# SAM9X75D5M register map
Vendor: Microchip Technology; Series: SAM9X7; File version: 0
Registers are 32-bit, read-write, reset 0x0 unless marked. A register's access mark holds for its fields unless they carry their own. Offsets are from the block's base; [hi:lo] are bit positions; {n}, {i} and the like mark numbered series; 'fields as' and 'values as' point back to an identical list.

## FLEXCOM0 (part 2 of 2) — Flexible Serial Communication
Base 0xF801C000; register names take the prefix FLEXCOM_
Same registers: FLEXCOM4 0xF0000000, FLEXCOM5 0xF0004000, FLEXCOM11 0xF0020000, FLEXCOM12 0xF0024000, FLEXCOM6 0xF8010000, FLEXCOM7 0xF8014000, FLEXCOM8 0xF8018000, FLEXCOM1 0xF8020000, FLEXCOM2 0xF8024000, FLEXCOM3 0xF8028000, FLEXCOM9 0xF8040000, FLEXCOM10 0xF8044000
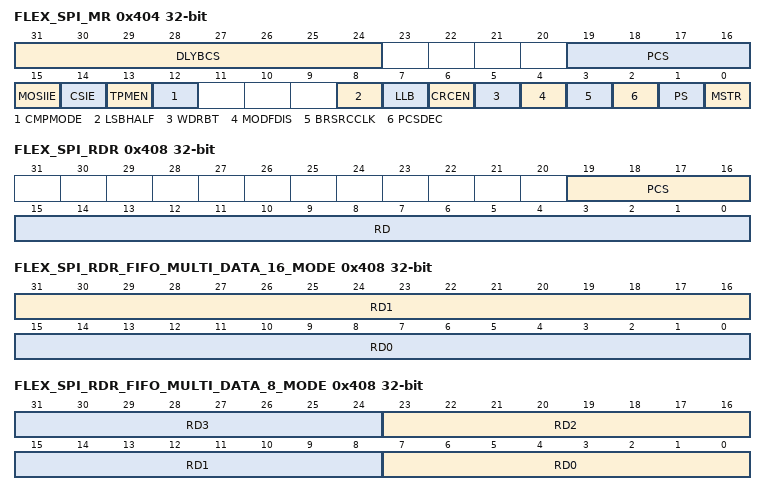
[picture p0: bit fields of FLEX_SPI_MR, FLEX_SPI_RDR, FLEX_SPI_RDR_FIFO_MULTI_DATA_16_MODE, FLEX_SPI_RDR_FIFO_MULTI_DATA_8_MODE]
0x404 FLEX_SPI_MR — SPI Mode Register
  [31:24] DLYBCS — Delay Between Chip Selects
  [19:16] PCS — Peripheral Chip Select
  [15] MOSIIE — MOSI Inversion Enable
    0=MOSI input is not inverted; 1=MOSI input is internally inverted before being processed by the SPI
  [14] CSIE — Chip Select Inversion Enable
    0=Chip select NPCS active polarity is low; 1=Chip select NPCS active polarity is high
  [13] TPMEN — Two-Pin Mode Enable
    0=Two-Pin mode is disabled; 1=Two-Pin mode is enabled
  [12] CMPMODE — Comparison Mode
    0=FLAG_ONLY (Any character is received and comparison function drives CMP flag.); 1=START_CONDITION (Comparison condition must be met to start reception of all incoming characters until REQCLR is set.)
  [8] LSBHALF — Last Bit Half Period Compatibility
    0=Normal SPI mode of operation: all bits have a 1-bit time duration (standard SPI mode); 1=Compatibility mode when connected to an SPI client having only a half bit period duration time for the last bit of the frame (non-standard SPI mode)
  [7] LLB — Local Loopback Enable
    0=Local loopback path disabled; 1=Local loopback path enabled
  [6] CRCEN — CRC Enable
    0=CRC calculation is disabled; 1=CRC calculation is enabled. BITS in FLEX_SPI_CSRx registers must be at value '0'.
  [5] WDRBT — Wait Data Read Before Transfer
    0=No Effect. In Host mode, a transfer can be initiated regardless of the FLEX_SPI_RDR state.; 1=In Host mode, a transfer can start only if FLEX_SPI_RDR is empty, i.e., does not contain any unread data. This mode prevents overrun error in reception.
  [4] MODFDIS — Mode Fault Detection
    0=Mode fault detection is enabled; 1=Mode fault detection is disabled
  [3] BRSRCCLK — Bit Rate Source Clock
    0=PERIPH_CLK (The peripheral clock is the source clock for the bit rate generation.); 1=GCLK (GCLK is the source clock for the bit rate generation, thus the bit rate can be independent of the core/peripheral clock.)
  [2] PCSDEC — Chip Select Decode
    0=The chip selects are directly connected to a peripheral device; 1=The four NPCS chip select lines are connected to a 4- to 16-bit decoder
  [1] PS — Peripheral Select
    0=Fixed Peripheral Select; 1=Variable Peripheral Select
  [0] MSTR — Host/Client Mode
    0=SPI is in Client mode; 1=SPI is in Host mode
0x408 FLEX_SPI_RDR ro — SPI Receive Data Register
  [19:16] PCS — Peripheral Chip Select
  [15:0] RD — Receive Data
0x408 FLEX_SPI_RDR_FIFO_MULTI_DATA_16_MODE ro (alternate view of FLEX_SPI_RDR) — SPI Receive Data Register
  [31:16] RD1 — Receive Data
  [15:0] RD0 — Receive Data
0x408 FLEX_SPI_RDR_FIFO_MULTI_DATA_8_MODE ro (alternate view of FLEX_SPI_RDR) — SPI Receive Data Register
  [8n+7:8n] RD{n} (n=0..3) — Receive Data
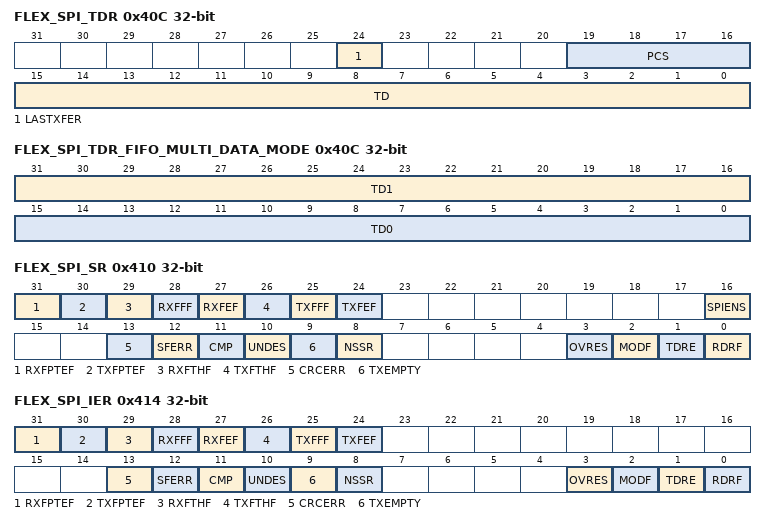
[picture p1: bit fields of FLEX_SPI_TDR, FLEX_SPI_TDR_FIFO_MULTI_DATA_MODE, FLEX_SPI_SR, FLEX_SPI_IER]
0x40C FLEX_SPI_TDR wo — SPI Transmit Data Register
  [24] LASTXFER — Last Transfer
    0=No effect; 1=The current NPCS is de-asserted after the transfer of the character written in TD. When FLEX_SPI_CSRx.CSAAT is set, the communication with the current serial peripheral can be closed by raising the corresponding NPCS line as soon as TD transfer is completed.
  [19:16] PCS — Peripheral Chip Select
  [15:0] TD — Transmit Data
0x40C FLEX_SPI_TDR_FIFO_MULTI_DATA_MODE wo (alternate view of FLEX_SPI_TDR) — SPI Transmit Data Register
  [31:16] TD1 — Transmit Data
  [15:0] TD0 — Transmit Data
0x410 FLEX_SPI_SR ro — SPI Status Register
  [31] RXFPTEF — Receive FIFO Pointer Error Flag
    0=No Receive FIFO pointer occurred; 1=Receive FIFO pointer error occurred. Receiver must be reset
  [30] TXFPTEF — Transmit FIFO Pointer Error Flag
    0=No Transmit FIFO pointer occurred; 1=Transmit FIFO pointer error occurred. Transceiver must be reset
  [29] RXFTHF — Receive FIFO Threshold Flag
    0=Number of unread data in Receive FIFO is below RXFTHRES threshold or RXFTH flag has been cleared; 1=Number of unread data in Receive FIFO has reached RXFTHRES threshold (changing states from 'below threshold' to 'equal to or above threshold')
  [28] RXFFF — Receive FIFO Full Flag
    0=Receive FIFO is not empty or RXFE flag has been cleared; 1=Receive FIFO has been filled (changing states from 'not full' to 'full')
  [27] RXFEF — Receive FIFO Empty Flag
    0=Receive FIFO is not empty or RXFE flag has been cleared; 1=Receive FIFO has been emptied (changing states from 'not empty' to 'empty')
  [26] TXFTHF — Transmit FIFO Threshold Flag (cleared on read)
    0=Number of data in Transmit FIFO is above TXFTHRES threshold; 1=Number of data in Transmit FIFO has reached TXFTHRES threshold since the last read of FLEX_SPI_SR
  [25] TXFFF — Transmit FIFO Full Flag (cleared on read)
    0=Transmit FIFO is not full or TXFF flag has been cleared; 1=Transmit FIFO has been filled since the last read of FLEX_SPI_SR
  [24] TXFEF — Transmit FIFO Empty Flag (cleared on read)
    0=Transmit FIFO is not empty; 1=Transmit FIFO has been emptied since the last read of FLEX_SPI_SR
  [16] SPIENS — SPI Enable Status
    0=SPI is disabled; 1=SPI is enabled
  [13] CRCERR — CRC Error (cleared on read)
    0=CRC calculation is disabled or no received frame contains a CRC error since the last read of FLEX_SPI_SR; 1=Since the last read of FLEX_SPI_SR, a received frame contains a CRC error
  [12] SFERR — Client Mode Frame Error (cleared on read)
    0=No frame error has been detected for a client access since the last read of FLEX_SPI_SR; 1=In Client mode, the chip select raised while the character defined in FLEX_SPI_CSR0.BITS was not complete
  [11] CMP — Comparison Status (cleared on read)
    0=No received character matched the comparison criteria programmed in VAL1 and VAL2 fields in FLEX_SPI_CMPR since the last read of FLEX_SPI_SR; 1=A received character matched the comparison criteria since the last read of FLEX_SPI_SR
  [10] UNDES — Underrun Error Status (Client mode only) (cleared on read)
    0=No underrun has been detected since the last read of FLEX_SPI_SR; 1=A transfer starts whereas no data has been loaded in FLEX_SPI_TDR, cleared when FLEX_SPI_SR is read
  [9] TXEMPTY — Transmission Registers Empty (cleared by writing FLEX_SPI_TDR)
    0=As soon as data is written in FLEX_SPI_TDR; 1=FLEX_SPI_TDR and internal shift register are empty. If a transfer delay has been defined, TXEMPTY is set after the end of this delay.
  [8] NSSR — NSS Rising (cleared on read)
    0=No rising edge detected on NSS pin since the last read of FLEX_SPI_SR; 1=A rising edge occurred on NSS pin since the last read of FLEX_SPI_SR
  [3] OVRES — Overrun Error Status (cleared on read)
    0=No overrun has been detected since the last read of FLEX_SPI_SR; 1=An overrun has occurred since the last read of FLEX_SPI_SR
  [2] MODF — Mode Fault Error (cleared on read)
    0=No mode fault has been detected since the last read of FLEX_SPI_SR; 1=A mode fault occurred since the last read of FLEX_SPI_SR
  [1] TDRE — Transmit Data Register Empty (cleared by writing FLEX_SPI_TDR)
    0=Data has been written to FLEX_SPI_TDR and not yet transferred to the internal shift register; 1=The last data written to FLEX_SPI_TDR has been transferred to the internal shift register
  [0] RDRF — Receive Data Register Full (cleared by reading FLEX_SPI_RDR)
    0=No data has been received since the last read of FLEX_SPI_RDR; 1=Data has been received and the received data has been transferred from the internal shift register to FLEX_SPI_RDR since the last read of FLEX_SPI_RDR
0x414 FLEX_SPI_IER wo — SPI Interrupt Enable Register
  [31] RXFPTEF — RXFPTEF Interrupt Enable
  [30] TXFPTEF — TXFPTEF Interrupt Enable
  [29] RXFTHF — RXFTHF Interrupt Enable
  [28] RXFFF — RXFFF Interrupt Enable
  [27] RXFEF — RXFEF Interrupt Enable
  [26] TXFTHF — TXFTHF Interrupt Enable
  [25] TXFFF — TXFFF Interrupt Enable
  [24] TXFEF — TXFEF Interrupt Enable
  [13] CRCERR — CRC Error Interrupt Enable
  [12] SFERR — Client Mode Frame Error Interrupt Enable
  [11] CMP — Comparison Interrupt Enable
  [10] UNDES — Underrun Error Interrupt Enable
  [9] TXEMPTY — Transmission Registers Empty Enable
  [8] NSSR — NSS Rising Interrupt Enable
  [3] OVRES — Overrun Error Interrupt Enable
  [2] MODF — Mode Fault Error Interrupt Enable
  [1] TDRE — SPI Transmit Data Register Empty Interrupt Enable
  [0] RDRF — Receive Data Register Full Interrupt Enable
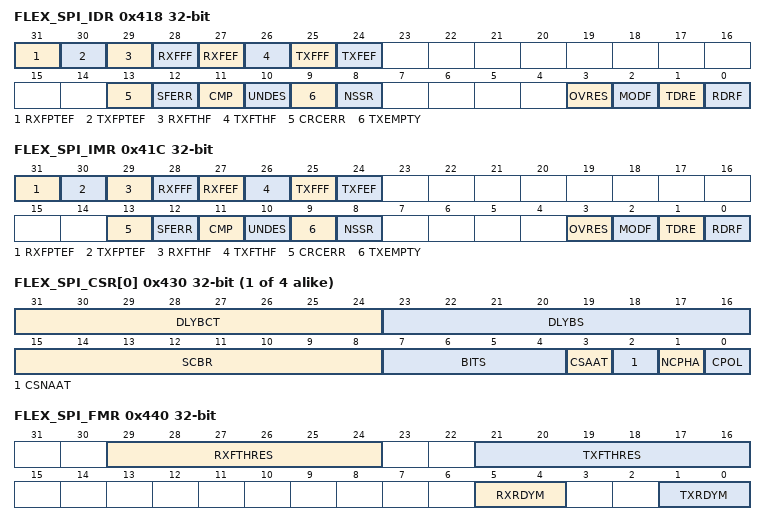
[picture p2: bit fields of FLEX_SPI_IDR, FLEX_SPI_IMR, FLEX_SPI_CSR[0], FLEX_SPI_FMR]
0x418 FLEX_SPI_IDR wo — SPI Interrupt Disable Register
  [31] RXFPTEF — RXFPTEF Interrupt Disable
  [30] TXFPTEF — TXFPTEF Interrupt Disable
  [29] RXFTHF — RXFTHF Interrupt Disable
  [28] RXFFF — RXFFF Interrupt Disable
  [27] RXFEF — RXFEF Interrupt Disable
  [26] TXFTHF — TXFTHF Interrupt Disable
  [25] TXFFF — TXFFF Interrupt Disable
  [24] TXFEF — TXFEF Interrupt Disable
  [13] CRCERR — CRC Error Interrupt Disable
  [12] SFERR — Client Mode Frame Error Interrupt Disable
  [11] CMP — Comparison Interrupt Disable
  [10] UNDES — Underrun Error Interrupt Disable
  [9] TXEMPTY — Transmission Registers Empty Disable
  [8] NSSR — NSS Rising Interrupt Disable
  [3] OVRES — Overrun Error Interrupt Disable
  [2] MODF — Mode Fault Error Interrupt Disable
  [1] TDRE — SPI Transmit Data Register Empty Interrupt Disable
  [0] RDRF — Receive Data Register Full Interrupt Disable
0x41C FLEX_SPI_IMR ro — SPI Interrupt Mask Register
  [31] RXFPTEF — RXFPTEF Interrupt Mask
  [30] TXFPTEF — TXFPTEF Interrupt Mask
  [29] RXFTHF — RXFTHF Interrupt Mask
  [28] RXFFF — RXFFF Interrupt Mask
  [27] RXFEF — RXFEF Interrupt Mask
  [26] TXFTHF — TXFTHF Interrupt Mask
  [25] TXFFF — TXFFF Interrupt Mask
  [24] TXFEF — TXFEF Interrupt Mask
  [13] CRCERR — CRC Error Interrupt Mask
  [12] SFERR — Client Mode Frame Error Interrupt Mask
  [11] CMP — Comparison Interrupt Mask
  [10] UNDES — Underrun Error Interrupt Mask
  [9] TXEMPTY — Transmission Registers Empty Mask
  [8] NSSR — NSS Rising Interrupt Mask
  [3] OVRES — Overrun Error Interrupt Mask
  [2] MODF — Mode Fault Error Interrupt Mask
  [1] TDRE — SPI Transmit Data Register Empty Interrupt Mask
  [0] RDRF — Receive Data Register Full Interrupt Mask
{0x430+4i} FLEX_SPI_CSR[{i}] (i=0..3) — SPI Chip Select Register x
  [31:24] DLYBCT — Delay Between Consecutive Transfers
  [23:16] DLYBS — Delay Before SPCK
  [15:8] SCBR — Serial Clock Bit Rate
  [7:4] BITS — Bits Per Transfer
    {v}={v+8}_BIT ({v+8} bits for transfer) (v=0..8)
  [3] CSAAT — Chip Select Active After Transfer
    0=The Peripheral Chip Select Line rises as soon as the last transfer is achieved; 1=The Peripheral Chip Select does not rise after the last transfer is achieved. It remains active until a new transfer is requested on a different chip select.
  [2] CSNAAT — Chip Select Not Active After Transfer (Ignored if CSAAT = 1)
    0=The Peripheral Chip Select does not rise between two transfers if the FLEX_SPI_TDR is reloaded before the end of the first transfer and if the two transfers occur on the same Chip Select; 1=The Peripheral Chip Select rises systematically after each transfer performed on the same client. It remains inactive after the end of transfer for a minimal duration of:
  [1] NCPHA — Clock Phase
    0=Data are changed on the leading edge of SPCK and captured on the following edge of SPCK; 1=Data are captured on the leading edge of SPCK and changed on the following edge of SPCK
  [0] CPOL — Clock Polarity
    0=The inactive state value of SPCK is logic level zero; 1=The inactive state value of SPCK is logic level one
0x440 FLEX_SPI_FMR — SPI FIFO Mode Register
  [29:24] RXFTHRES — Receive FIFO Threshold
  [21:16] TXFTHRES — Transmit FIFO Threshold
  [5:4] RXRDYM — Receive Data Register Full Mode
    0=ONE_DATA (RDRF will be at level '1' when at least one unread data is in the receive FIFO. When DMA is enabled to transfer data and FLEX_SPI_CSR0.BITS=0 (8 bits transfered on SPI line), the chunk of 1 byte must be configured in the DMA. When FLEX_SPI_CSR0.BITS>0 (9 to 16 bits transfered on SPI line), the chunk of 1 halfword must be configured in the DMA. If the transfer is performed by software, the access type can be defined as byte or halfword depending on FLEX_SPI_CSR0.BITS.); 1=TWO_DATA (RDRF will be at level '1' when at least two unread data are in the receive FIFO. To minimize system bus load, when DMA is enabled to transfer data and FLEX_SPI_CSR0.BITS=0 (8 bits transfered on SPI line), the chunk of 1 halfword (1 halfword carries 2 bytes) must be configured in the DMA. When FLEX_SPI_CSR0.BITS>0 (9 to 16 bits transfered on SPI line), the chunk of 1 word (1 word carries 2 halfwords) must be configured in the DMA. If the transfer is performed by software, the access type can be defined as halfword (2 bytes per access, 1 access when FLEX_SPI_CSR0.BITS=0), or word (2 halfwords per access, 2 accesses when FLEX_SPI_CSR0.BITS>0).); 2=FOUR_DATA (RDRF will be at level '1' when at least four unread data are in the receive FIFO. To minimize system bus load, when DMA is enabled to transfer data and FLEX_SPI_CSR0.BITS=0 (8 bits transfered on SPI line), the chunk of 1 word (1 halfword carries 4 bytes) must be configured in the DMA. When FLEX_SPI_CSR0.BITS>0 (9 to 16 bits transfered on SPI line), the chunk of 2 words (1 word carries 4 bytes) must be configured in the DMA. If the transfer is performed by software, the access type can be defined as word (4 bytes per access, 1 access when FLEX_SPI_CSR0.BITS=0 or 2 halfwords per access, 2 accesses when FLEX_SPI_CSR0.BITS>0).)
  [1:0] TXRDYM — Transmit Data Register Empty Mode
    0=ONE_DATA (TDRE will be at level '1' when at least one data can be written in the transmit FIFO. When DMA is enabled to transfer data, the chunk of 1 data (byte or halfword) must be configured in the DMA depending on FLEX_SPI_CSR0.BITS. If the transfer is performed by software, the access type (byte, halfword) must be defined depending on FLEX_SPI_CSR0.BITS.); 1=TWO_DATA (TDRE will be at level '1' when at least two data can be written in the transmit FIFO. FIFO. To minimize system bus load, when DMA is enabled to transfer data, the chunk of 1 word (1 word carries 2 data) must be configured in the DMA. If the transfer is performed by software, the access type must be defined as word (2 data per access, 1 access).)
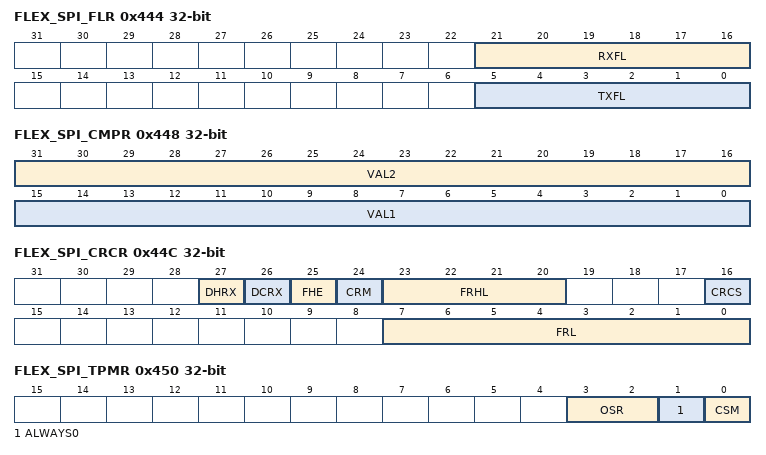
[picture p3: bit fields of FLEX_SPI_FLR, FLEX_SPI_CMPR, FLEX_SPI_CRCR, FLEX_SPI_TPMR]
0x444 FLEX_SPI_FLR ro — SPI FIFO Level Register
  [21:16] RXFL — Receive FIFO Level
    0=There is no unread data in the Receive FIFO
  [5:0] TXFL — Transmit FIFO Level
    0=There is no data in the Transmit FIFO
0x448 FLEX_SPI_CMPR — SPI Comparison Register
  [31:16] VAL2 — Second Comparison Value for Received Character
  [15:0] VAL1 — First Comparison Value for Received Character
0x44C FLEX_SPI_CRCR — SPI CRC Register
  [27] DHRX — Disable Header Receiving
    0=Header is received and supplied to FLEX_SPI_RDR as a classic data; 1=Header is received and checked but not supplied to FLEX_SPI_RDR (RDRF will not rise upon Header receiving)
  [26] DCRX — Disable CRC Receiving
    0=CRC is received and supplied to FLEX_SPI_RDR as a classic data; 1=CRC is received and checked but not supplied to FLEX_SPI_RDR (RDRF will not rise upon CRC receiving)
  [25] FHE — Frame Header Excluded
    0=The frame header is included in the CRC calculation; 1=The frame header is excluded from the CRC calculation
  [24] CRM — Continuous Read Mode
    0=A header is sent every frame in case of contiguous frames (without de-asserting the corresponding NPCS); 1=A header is sent only on the first frame in case of contiguous frames (without de-asserting the corresponding NPCS)
  [23:20] FRHL — Frame Header Length
  [16] CRCS — CRC Size
    0=16B_CRC (CRC size is 16 bits.); 1=32B_CRC (CRC size is 32 bits.)
  [7:0] FRL — Frame Length
0x450 FLEX_SPI_TPMR — SPI Two-Pin Mode Register
  [3:2] OSR — OverSampling Rate
  [1] ALWAYS0 — Always Written to 0
  [0] CSM — Chip Select Mode
    0=Chip select is not driven; 1=Chip select is driven and can be used to control enable pin of external device. Depending on FLEX_SPI_MR.PCSDEC, an external decoder can be used to minimize the number of IOs used.
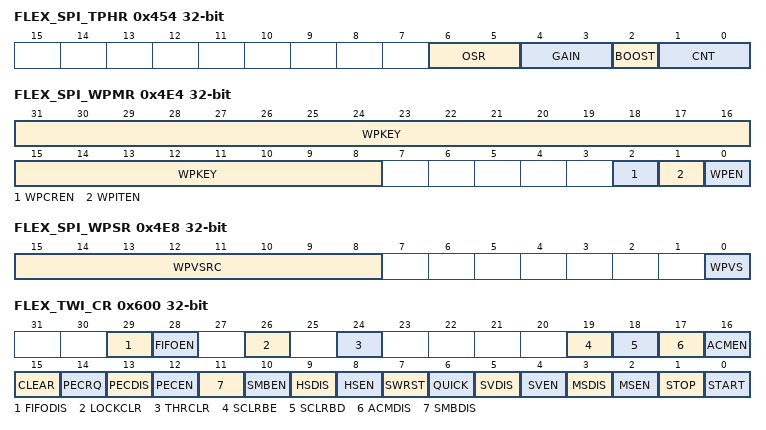
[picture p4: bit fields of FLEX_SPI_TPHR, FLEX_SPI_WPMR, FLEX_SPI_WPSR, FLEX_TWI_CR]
0x454 FLEX_SPI_TPHR ro — SPI Two-Pin Header Register
  [6:5] OSR — OverSampling Rate
  [4:3] GAIN
  [2] BOOST — Current Boost
  [1:0] CNT — Frame Counter
0x4E4 FLEX_SPI_WPMR — SPI Write Protection Mode Register
  [31:8] WPKEY — Write Protection Key
    0x535049=PASSWD (Writing any other value in this field aborts the write operation of bits WPEN, WPITEN and WPCREN. Always reads as 0)
  [2] WPCREN — Write Protection Control Enable
    0=Disables the write protection on control register if WPKEY corresponds to 0x535049 ('SPI' in ASCII); 1=Enables the write protection on control register if WPKEY corresponds to 0x535049 ('SPI' in ASCII)
  [1] WPITEN — Write Protection Interrupt Enable
    0=Disables the write protection on interrupt registers if WPKEY corresponds to 0x535049 ('SPI' in ASCII); 1=Enables the write protection on interrupt registers if WPKEY corresponds to 0x535049 ('SPI' in ASCII)
  [0] WPEN — Write Protection Enable
    0=Disables the write protection if WPKEY corresponds to 0x535049 ('SPI' in ASCII); 1=Enables the write protection if WPKEY corresponds to 0x535049 ('SPI' in ASCII)
0x4E8 FLEX_SPI_WPSR ro — SPI Write Protection Status Register
  [15:8] WPVSRC — Write Protection Violation Source
  [0] WPVS — Write Protection Violation Status
    0=No write protect violation has occurred since the last read of FLEX_SPI_WPSR; 1=A write protect violation has occurred since the last read of FLEX_SPI_WPSR. If this violation is an unauthorized
0x600 FLEX_TWI_CR wo — TWI Control Register
  [29] FIFODIS — FIFO Disable
    0=No effect; 1=Disable the Transmit and Receive FIFOs
  [28] FIFOEN — FIFO Enable
    0=No effect; 1=Enable the Transmit and Receive FIFOs
  [26] LOCKCLR — Lock Clear
    0=No effect; 1=Clear the TWI FSM lock
  [24] THRCLR — Transmit Holding Register Clear
    0=No effect; 1=Clear the Transmit Holding Register and set TXRDY, TXCOMP flags
  [19] SCLRBE — SCL Rise Boost Enable
    0=No effect; 1=SCL rise time is boosted in High-Speed mode. Duration of the boost is configured with FLEX_TWI_MMR.SCLRBL. See Section 10.3.12.2 'SCL Rising Time Control' for details.
  [18] SCLRBD — SCL Rise Boost Disable
    0=No effect; 1=SCL rise time boost is disabled. See Section 10.3.12.2 'SCL Rising Time Control' for details.
  [17] ACMDIS — Alternative Command Mode Disable
    0=No effect; 1=Alternative Command mode disabled
  [16] ACMEN — Alternative Command Mode Enable
    0=No effect; 1=Alternative Command mode enabled
  [15] CLEAR — Bus CLEAR Command
    0=No effect; 1=When Host mode is enabled and TWD (SDA)=1, send a Bus Clear Command
  [14] PECRQ — PEC Request
    0=No effect; 1=A PEC check or transmission is requested
  [13] PECDIS — Packet Error Checking Disable
    0=No effect; 1=SMBus PEC (CRC) generation and check disabled
  [12] PECEN — Packet Error Checking Enable
    0=No effect; 1=SMBus PEC (CRC) generation and check enabled
  [11] SMBDIS — SMBus Mode Disabled
    0=No effect; 1=SMBus mode disabled
  [10] SMBEN — SMBus Mode Enabled
    0=No effect; 1=If SMBDIS = 0, SMBus mode enabled
  [9] HSDIS — TWI High-Speed Mode Disabled
    0=No effect; 1=High-speed mode disabled
  [8] HSEN — TWI High-Speed Mode Enabled
    0=No effect; 1=High-speed mode enabled
  [7] SWRST — Software Reset
    0=No effect; 1=Equivalent to a system reset
  [6] QUICK — SMBus Quick Command
    0=No effect; 1=If Host mode is enabled, a SMBus Quick Command is sent
  [5] SVDIS — TWI Client Mode Disabled
    0=No effect; 1=Client mode is disabled. The shifter and holding characters (if it contains data) are transmitted in case of read operation. In write operation, the character being transferred must be completely received before disabling.
  [4] SVEN — TWI Client Mode Enabled
    0=No effect; 1=Enables Client mode (SVDIS must be written to 0)
  [3] MSDIS — TWI Host Mode Disabled
    0=No effect; 1=Host mode is disabled, all pending data is transmitted. The shifter and holding characters (if it contains data) are transmitted in case of write operation. In read operation, the character being transferred must be completely received before disabling.
  [2] MSEN — TWI Host Mode Enabled
    0=No effect; 1=Enables Host mode (MSDIS must be written to 0)
  [1] STOP — Send a STOP Condition
    0=No effect; 1=STOP condition is sent just after completing the current byte transmission in Host Read mode
  [0] START — Send a START Condition
    0=No effect; 1=A frame beginning with a START bit is transmitted according to the features defined in the TWI Host Mode Register (FLEX_TWI_MMR)
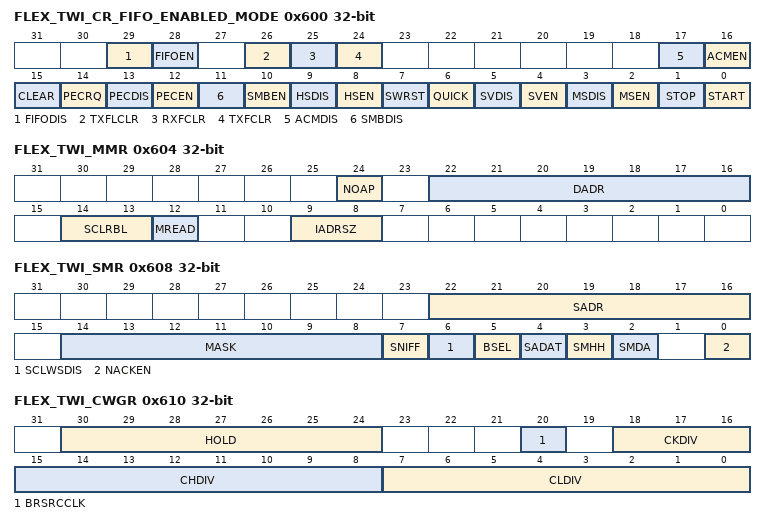
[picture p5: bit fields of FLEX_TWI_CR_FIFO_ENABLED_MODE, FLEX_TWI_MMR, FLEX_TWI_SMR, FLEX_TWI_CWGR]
0x600 FLEX_TWI_CR_FIFO_ENABLED_MODE wo (alternate view of FLEX_TWI_CR) — TWI Control Register
  [29] FIFODIS — FIFO Disable
    0=No effect; 1=Disable the Transmit and Receive FIFOs
  [28] FIFOEN — FIFO Enable
    0=No effect; 1=Enable the Transmit and Receive FIFOs
  [26] TXFLCLR — Transmit FIFO Lock CLEAR
    0=No effect; 1=Clears the Transmit FIFO Lock
  [25] RXFCLR — Receive FIFO Clear
    0=No effect; 1=Empties the Receive FIFO
  [24] TXFCLR — Transmit FIFO Clear
    0=No effect; 1=Empties the Transmit FIFO
  [17] ACMDIS — Alternative Command Mode Disable
    0=No effect; 1=Alternative Command mode disabled
  [16] ACMEN — Alternative Command Mode Enable
    0=No effect; 1=Alternative Command mode enabled
  [15] CLEAR — Bus CLEAR Command
    values as FLEX_TWI_CR.CLEAR
  [14] PECRQ — PEC Request
    0=No effect; 1=A PEC check or transmission is requested
  [13] PECDIS — Packet Error Checking Disable
    0=No effect; 1=SMBus PEC (CRC) generation and check disabled
  [12] PECEN — Packet Error Checking Enable
    0=No effect; 1=SMBus PEC (CRC) generation and check enabled
  [11] SMBDIS — SMBus Mode Disabled
    0=No effect; 1=SMBus mode disabled
  [10] SMBEN — SMBus Mode Enabled
    0=No effect; 1=If SMBDIS = 0, SMBus mode enabled
  [9] HSDIS — TWI High-Speed Mode Disabled
    0=No effect; 1=High-speed mode disabled
  [8] HSEN — TWI High-Speed Mode Enabled
    0=No effect; 1=High-speed mode enabled
  [7] SWRST — Software Reset
    0=No effect; 1=Equivalent to a system reset
  [6] QUICK — SMBus Quick Command
    values as FLEX_TWI_CR.QUICK
  [5] SVDIS — TWI Client Mode Disabled
    values as FLEX_TWI_CR.SVDIS
  [4] SVEN — TWI Client Mode Enabled
    values as FLEX_TWI_CR.SVEN
  [3] MSDIS — TWI Host Mode Disabled
    values as FLEX_TWI_CR.MSDIS
  [2] MSEN — TWI Host Mode Enabled
    values as FLEX_TWI_CR.MSEN
  [1] STOP — Send a STOP Condition
    values as FLEX_TWI_CR.STOP
  [0] START — Send a START Condition
    values as FLEX_TWI_CR.START
0x604 FLEX_TWI_MMR — TWI Host Mode Register
  [24] NOAP — No Auto-Stop On NACK Error
    0=A stop condition is sent automatically upon Not-Acknowledge error detection; 1=No automatic action is performed upon Not-Acknowledge error detection
  [22:16] DADR — Device Address
  [14:13] SCLRBL — SCL Rise Boost Level
  [12] MREAD — Host Read Direction
    0=Host write direction; 1=Host read direction
  [9:8] IADRSZ — Internal Device Address Size
    0=NONE (No internal device address); 1=1_BYTE (One-byte internal device address); 2=2_BYTE (Two-byte internal device address); 3=3_BYTE (Three-byte internal device address)
0x608 FLEX_TWI_SMR — TWI Client Mode Register
  [22:16] SADR — Client Address
  [14:8] MASK — Client Address Mask
  [7] SNIFF — Client Sniffer Mode
    0=Client Sniffer mode is disabled; 1=Client Sniffer mode is enabled
  [6] SCLWSDIS — Clock Wait State Disable
    0=No effect; 1=Clock stretching disabled in Client mode, OVRE and UNRE will indicate overrun and underrun
  [5] BSEL — TWI Bus Selection
    0=TWI analyzes the TWCK and TWD pins from its TWI bus; 1=TWIn analyzes the TWCK and TWD pins of the peripheral TWIn-1 (TWI0 analyzes TWImax)
  [4] SADAT — Client Address Treated as Data
    0=Client address is handled normally (will not trig RXRDY flag and will not fill FLEX_TWI_RHR upon reception); 1=Client address is handled as data field, RXRDY will be set and FLEX_TWI_RHR filled upon client address reception
  [3] SMHH — SMBus Host Header
    0=Acknowledge of the SMBus Host Header disabled; 1=Acknowledge of the SMBus Host Header enabled
  [2] SMDA — SMBus Default Address
    0=Acknowledge of the SMBus Default Address disabled; 1=Acknowledge of the SMBus Default Address enabled
  [0] NACKEN — Client Receiver Data Phase NACK Enable
    0=Normal value to be returned in the ACK cycle of the data phase in Client Receiver mode; 1=NACK value to be returned in the ACK cycle of the data phase in Client Receiver mode
0x60C FLEX_TWI_IADR — TWI Internal Address Register
  [23:0] IADR — Internal Address
0x610 FLEX_TWI_CWGR — TWI Clock Waveform Generator Register
  [30:24] HOLD — TWD Hold Time Versus TWCK Falling
  [20] BRSRCCLK — Bit Rate Source Clock
    values as FLEX_SPI_MR.BRSRCCLK
  [18:16] CKDIV — Clock Divider
  [15:8] CHDIV — Clock High Divider
  [7:0] CLDIV — Clock Low Divider
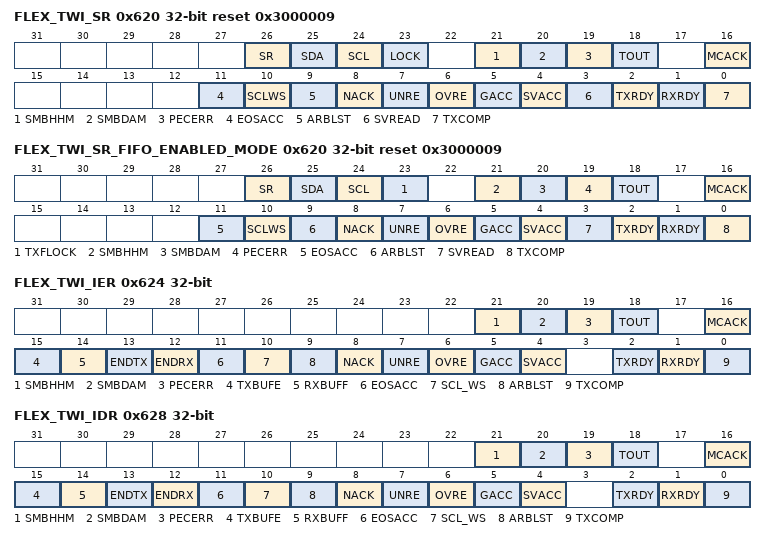
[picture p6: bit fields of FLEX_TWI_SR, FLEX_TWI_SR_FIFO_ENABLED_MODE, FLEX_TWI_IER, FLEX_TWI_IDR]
0x620 FLEX_TWI_SR ro reset 0x3000009 — TWI Status Register
  [26] SR — Start Repeated
    0=No repeated start has been detected since last FLEX_TWI_SR read; 1=At least one repeated start has been detected since last FLEX_TWI_SR read
  [25] SDA — SDA Line Value
    0=SDA line sampled value is '0'; 1=SDA line sampled value is '1'
  [24] SCL — SCL Line Value
    0=SCL line sampled value is '0'; 1=SCL line sampled value is '1.'
  [23] LOCK — TWI Lock Due to Frame Errors
    0=The TWI is not locked; 1=The TWI is locked due to frame errors (see Section 10.3.14 'Handling Errors in Alternative Command' and Section 10.6 'TWI FIFOs')
  [21] SMBHHM — SMBus Host Header Address Match (cleared on read)
    0=No SMBus Host Header Address received; 1=A SMBus Host Header Address was received
  [20] SMBDAM — SMBus Default Address Match (cleared on read)
    0=No SMBus Default Address received; 1=A SMBus Default Address was received
  [19] PECERR — PEC Error (cleared on read)
    0=No SMBus PEC error occurred; 1=A SMBus PEC error occurred
  [18] TOUT — Timeout Error (cleared on read)
    0=No SMBus timeout occurred; 1=SMBus timeout occurred
  [16] MCACK — Host Code Acknowledge (cleared on read)
    0=No host code has been received; 1=A host code has been received
  [11] EOSACC — End Of Client Access (cleared on read)
    0=A client access is being performed; 1=Client Access is finished. End Of Client Access is automatically set as soon as SVACC is reset.
  [10] SCLWS — Clock Wait State
    0=The clock is not stretched; 1=The clock is stretched. FLEX_TWI_THR / FLEX_TWI_RHR buffer is not filled / emptied before the transmission / reception of a new character.
  [9] ARBLST — Arbitration Lost (cleared on read)
    0=Arbitration won; 1=Arbitration lost. Another host of the TWI bus has won the multi-host arbitration. TXCOMP is set at the same time.
  [8] NACK — Not Acknowledged (cleared on read)
    0=Each data byte has been correctly received by the far-end side TWI client component; 1=A data or address byte has not been acknowledged by the client component. Set at the same time as TXCOMP.
  [7] UNRE — Underrun Error (cleared on read)
    0=FLEX_TWI_THR has been filled on time; 1=FLEX_TWI_THR has not been filled on time
  [6] OVRE — Overrun Error (cleared on read)
    0=FLEX_TWI_RHR has not been loaded while RXRDY was set; 1=FLEX_TWI_RHR has been loaded while RXRDY was set. Reset by read in FLEX_TWI_SR when TXCOMP is set.
  [5] GACC — General Call Access (cleared on read)
    0=No general call has been detected; 1=A general call has been detected. After the detection of general call, if need be, the user may acknowledge this access and decode the following bytes and respond according to the value of the bytes.
  [4] SVACC — Client Access
    0=TWI is not addressed. SVACC is automatically cleared after a NACK or a STOP condition is detected.; 1=Indicates that the address decoding sequence has matched (a host has sent SADR). SVACC remains high until a NACK or a STOP condition is detected.
  [3] SVREAD — Client Read
    0=Indicates that a write access is performed by a host; 1=Indicates that a read access is performed by a host
  [2] TXRDY — Transmit Holding Register Ready (cleared by writing FLEX_TWI_THR)
    0=The transmit holding register has not been transferred into the internal shifter. Set to 0 when writing into FLEX_TWI_THR.; 1=As soon as a data byte is transferred from FLEX_TWI_THR to internal shifter or if a NACK error is detected, TXRDY is set at the same time as TXCOMP and NACK. TXRDY is also set when MSEN is set (enables TWI).
  [1] RXRDY — Receive Holding Register Ready (cleared when reading FLEX_TWI_RHR)
    0=No character has been received since the last FLEX_TWI_RHR read operation; 1=A byte has been received in FLEX_TWI_RHR since the last read
  [0] TXCOMP — Transmission Completed (cleared by writing FLEX_TWI_THR)
    0=During the length of the current frame; 1=When both the holding register and the internal shifter are empty and STOP condition has been sent
0x620 FLEX_TWI_SR_FIFO_ENABLED_MODE ro reset 0x3000009 (alternate view of FLEX_TWI_SR) — TWI Status Register
  [26] SR — Start Repeated
    values as FLEX_TWI_SR.SR
  [25] SDA — SDA Line Value
    values as FLEX_TWI_SR.SDA
  [24] SCL — SCL Line Value
    values as FLEX_TWI_SR.SCL
  [23] TXFLOCK — Transmit FIFO Lock
    0=The Transmit FIFO is not locked; 1=The Transmit FIFO is locked
  [21] SMBHHM — SMBus Host Header Address Match (cleared on read)
    values as FLEX_TWI_SR.SMBHHM
  [20] SMBDAM — SMBus Default Address Match (cleared on read)
    values as FLEX_TWI_SR.SMBDAM
  [19] PECERR — PEC Error (cleared on read)
    0=No SMBus PEC error occurred; 1=A SMBus PEC error occurred
  [18] TOUT — Timeout Error (cleared on read)
    0=No SMBus timeout occurred; 1=SMBus timeout occurred
  [16] MCACK — Host Code Acknowledge (cleared on read)
    values as FLEX_TWI_SR.MCACK
  [11] EOSACC — End Of Client Access (cleared on read)
    values as FLEX_TWI_SR.EOSACC
  [10] SCLWS — Clock Wait State
    values as FLEX_TWI_SR.SCLWS
  [9] ARBLST — Arbitration Lost (cleared on read)
    values as FLEX_TWI_SR.ARBLST
  [8] NACK — Not Acknowledged (cleared on read)
    values as FLEX_TWI_SR.NACK
  [7] UNRE — Underrun Error (cleared on read)
    values as FLEX_TWI_SR.UNRE
  [6] OVRE — Overrun Error (cleared on read)
    values as FLEX_TWI_SR.OVRE
  [5] GACC — General Call Access (cleared on read)
    values as FLEX_TWI_SR.GACC
  [4] SVACC — Client Access
    values as FLEX_TWI_SR.SVACC
  [3] SVREAD — Client Read
    values as FLEX_TWI_SR.SVREAD
  [2] TXRDY — Transmit Holding Register Ready (cleared by writing FLEX_TWI_THR)
    values as FLEX_TWI_SR.TXRDY
  [1] RXRDY — Receive Holding Register Ready (cleared when reading FLEX_TWI_RHR)
    values as FLEX_TWI_SR.RXRDY
  [0] TXCOMP — Transmission Completed (cleared by writing FLEX_TWI_THR)
    0=During the length of the current frame; 1=When both holding register and internal shifter are empty and STOP condition has been sent
0x624 FLEX_TWI_IER wo — TWI Interrupt Enable Register
  [21] SMBHHM — SMBus Host Header Address Match Interrupt Enable
  [20] SMBDAM — SMBus Default Address Match Interrupt Enable
  [19] PECERR — PEC Error Interrupt Enable
  [18] TOUT — Timeout Error Interrupt Enable
  [16] MCACK — Host Code Acknowledge Interrupt Enable
  [15] TXBUFE — Transmit Buffer Empty Interrupt Enable
  [14] RXBUFF — Receive Buffer Full Interrupt Enable
  [13] ENDTX — End of Transmit Buffer Interrupt Enable
  [12] ENDRX — End of Receive Buffer Interrupt Enable
  [11] EOSACC — End Of Client Access Interrupt Enable
  [10] SCL_WS — Clock Wait State Interrupt Enable
  [9] ARBLST — Arbitration Lost Interrupt Enable
  [8] NACK — Not Acknowledge Interrupt Enable
  [7] UNRE — Underrun Error Interrupt Enable
  [6] OVRE — Overrun Error Interrupt Enable
  [5] GACC — General Call Access Interrupt Enable
  [4] SVACC — Client Access Interrupt Enable
  [2] TXRDY — Transmit Holding Register Ready Interrupt Enable
  [1] RXRDY — Receive Holding Register Ready Interrupt Enable
  [0] TXCOMP — Transmission Completed Interrupt Enable
0x628 FLEX_TWI_IDR wo — TWI Interrupt Disable Register
  [21] SMBHHM — SMBus Host Header Address Match Interrupt Disable
  [20] SMBDAM — SMBus Default Address Match Interrupt Disable
  [19] PECERR — PEC Error Interrupt Disable
  [18] TOUT — Timeout Error Interrupt Disable
  [16] MCACK — Host Code Acknowledge Interrupt Disable
  [15] TXBUFE — Transmit Buffer Empty Interrupt Disable
  [14] RXBUFF — Receive Buffer Full Interrupt Disable
  [13] ENDTX — End of Transmit Buffer Interrupt Disable
  [12] ENDRX — End of Receive Buffer Interrupt Disable
  [11] EOSACC — End Of Client Access Interrupt Disable
  [10] SCL_WS — Clock Wait State Interrupt Disable
  [9] ARBLST — Arbitration Lost Interrupt Disable
  [8] NACK — Not Acknowledge Interrupt Disable
  [7] UNRE — Underrun Error Interrupt Disable
  [6] OVRE — Overrun Error Interrupt Disable
  [5] GACC — General Call Access Interrupt Disable
  [4] SVACC — Client Access Interrupt Disable
  [2] TXRDY — Transmit Holding Register Ready Interrupt Disable
  [1] RXRDY — Receive Holding Register Ready Interrupt Disable
  [0] TXCOMP — Transmission Completed Interrupt Disable
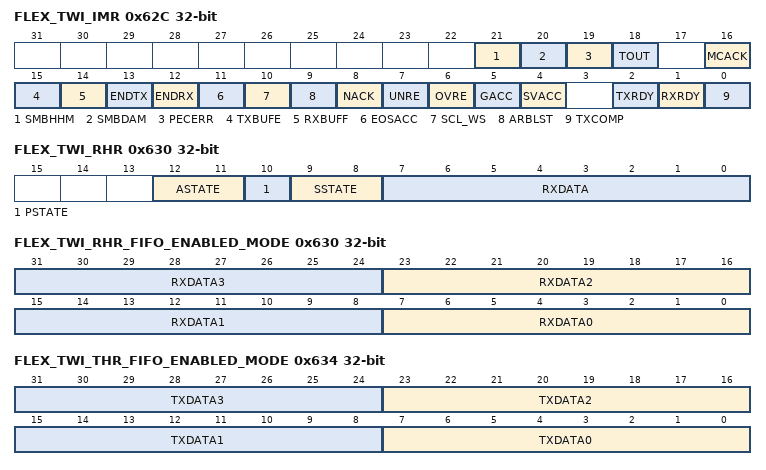
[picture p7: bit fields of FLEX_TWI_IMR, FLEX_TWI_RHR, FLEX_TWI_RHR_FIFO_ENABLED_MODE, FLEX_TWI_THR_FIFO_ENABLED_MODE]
0x62C FLEX_TWI_IMR ro — TWI Interrupt Mask Register
  [21] SMBHHM — SMBus Host Header Address Match Interrupt Mask
  [20] SMBDAM — SMBus Default Address Match Interrupt Mask
  [19] PECERR — PEC Error Interrupt Mask
  [18] TOUT — Timeout Error Interrupt Mask
  [16] MCACK — Host Code Acknowledge Interrupt Mask
  [15] TXBUFE — Transmit Buffer Empty Interrupt Mask
  [14] RXBUFF — Receive Buffer Full Interrupt Mask
  [13] ENDTX — End of Transmit Buffer Interrupt Mask
  [12] ENDRX — End of Receive Buffer Interrupt Mask
  [11] EOSACC — End Of Client Access Interrupt Mask
  [10] SCL_WS — Clock Wait State Interrupt Mask
  [9] ARBLST — Arbitration Lost Interrupt Mask
  [8] NACK — Not Acknowledge Interrupt Mask
  [7] UNRE — Underrun Error Interrupt Mask
  [6] OVRE — Overrun Error Interrupt Mask
  [5] GACC — General Call Access Interrupt Mask
  [4] SVACC — Client Access Interrupt Mask
  [2] TXRDY — Transmit Holding Register Ready Interrupt Mask
  [1] RXRDY — Receive Holding Register Ready Interrupt Mask
  [0] TXCOMP — Transmission Completed Interrupt Mask
0x630 FLEX_TWI_RHR ro — TWI Receive Holding Register
  [12:11] ASTATE — Acknowledge State (Client Sniffer Mode only)
    0=NONE (No Acknowledge or Nacknowledge detected after previously logged data); 1=ACK (Acknowledge (A) detected after previously logged data); 2=NACK (Nacknowledge (NA) detected after previously logged data); 3=UNDEF (Not defined)
  [10] PSTATE — Stop State (Client Sniffer Mode only)
    0=No STOP (P) detected after previous logged data; 1=Stop detected (P) after previous logged data
  [9:8] SSTATE — Start State (Client Sniffer Mode only)
    0=NOSTART (No START detected with the logged data); 1=START (START (S) detected with the logged data); 2=RSTART (Repeated START (Sr) detected with the logged data); 3=UNDEF (Not defined)
  [7:0] RXDATA — Host or Client Receive Holding Data
0x630 FLEX_TWI_RHR_FIFO_ENABLED_MODE ro (alternate view of FLEX_TWI_RHR) — TWI Receive Holding Register
  [8n+7:8n] RXDATA{n} (n=0..3) — Host or Client Receive Holding Data {n}
0x634 FLEX_TWI_THR wo — TWI Transmit Holding Register
  [7:0] TXDATA — Host or Client Transmit Holding Data
0x634 FLEX_TWI_THR_FIFO_ENABLED_MODE wo (alternate view of FLEX_TWI_THR) — TWI Transmit Holding Register
  [8n+7:8n] TXDATA{n} (n=0..3) — Host or Client Transmit Holding Data {n}
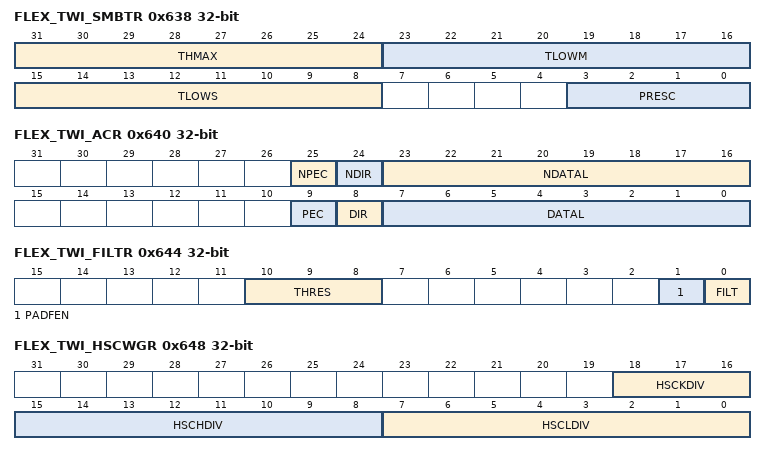
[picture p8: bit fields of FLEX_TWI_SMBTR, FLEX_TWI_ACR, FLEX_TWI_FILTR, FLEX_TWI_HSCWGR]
0x638 FLEX_TWI_SMBTR — TWI SMBus Timing Register
  [31:24] THMAX — Clock High Maximum Cycles
  [23:16] TLOWM — Host Clock Stretch Maximum Cycles
    0=TLOW:MEXT timeout check disabled
  [15:8] TLOWS — Client Clock Stretch Maximum Cycles
    0=TLOW:SEXT timeout check disabled
  [3:0] PRESC — SMBus Clock Prescaler
0x63C FLEX_TWI_HSR — TWI High Speed Register
  [7:0] MCODE — TWI High Speed Host Code
0x640 FLEX_TWI_ACR — TWI Alternative Command Register
  [25] NPEC — Next PEC Request (SMBus Mode only)
    0=The next transfer does not use a PEC byte; 1=The next transfer uses a PEC byte
  [24] NDIR — Next Transfer Direction
    0=Write direction; 1=Read direction
  [23:16] NDATAL — Next Data Length
    0=No data to send (see Section 10.3.11 'SMBus Quick Command (Host Mode Only)')
  [9] PEC — PEC Request (SMBus Mode only)
    0=The transfer does not use a PEC byte; 1=The transfer uses a PEC byte
  [8] DIR — Transfer Direction
    0=Write direction; 1=Read direction
  [7:0] DATAL — Data Length
    values as NDATAL
0x644 FLEX_TWI_FILTR — TWI Filter Register
  [10:8] THRES — Digital Filter Threshold
    0=No filtering applied on TWI inputs
  [1] PADFEN — PAD Filter Enable
    0=PAD analog filter is disabled; 1=PAD analog filter is enabled. (The analog filter must be enabled if High-speed mode is enabled.)
  [0] FILT — RX Digital Filter
    0=No filtering applied on TWI inputs; 1=TWI input filtering is active. (Only in Standard and Fast modes)
0x648 FLEX_TWI_HSCWGR — TWI High Speed Clock Waveform Generator Register
  [18:16] HSCKDIV — High Speed Clock Divider
  [15:8] HSCHDIV — High Speed Clock High Divider
  [7:0] HSCLDIV — High Speed Clock Low Divider
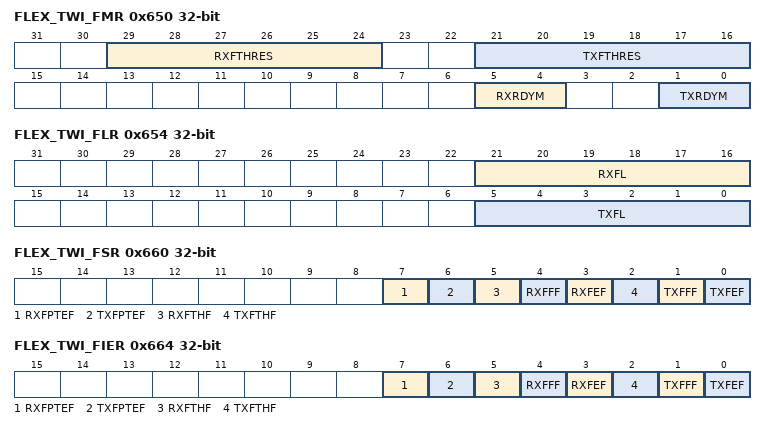
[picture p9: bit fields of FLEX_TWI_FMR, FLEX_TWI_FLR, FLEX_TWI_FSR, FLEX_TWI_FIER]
0x650 FLEX_TWI_FMR — TWI FIFO Mode Register
  [29:24] RXFTHRES — Receive FIFO Threshold
  [21:16] TXFTHRES — Transmit FIFO Threshold
  [5:4] RXRDYM — Receiver Ready Mode
    0=ONE_DATA (RXRDY will be at level '1' when at least one unread data is in the receive FIFO. When DMA is enabled to transfer data the chunk of 1 byte must be configured in the DMA. If the transfer is performed by software, the access type (byte, halfword) must be defined accordingly.); 1=TWO_DATA (RXRDY will be at level '1' when at least two unread data are in the receive FIFO. To minimize system bus load, when DMA is enabled to transfer data, the chunk of 1 halfword (1 halfword carries 2 bytes) must be configured in the DMA. If the transfer is performed by software, the access type can be defined as byte (1 byte per access, 2 accesses) or halfword (2 bytes per access, 1 single access).); 2=FOUR_DATA (RXRDY will be at level '1' when at least four unread data are in the receive FIFO. To minimize system bus load, when DMA is enabled to transfer data, the chunk of 1 word (1 word carries 4 bytes) must be configured in the DMA. If the transfer is performed by software, the access type can be defined as byte (1 byte per access, 4 accesses), halfword (2 bytes per access, 2 accesses) or word (4 bytes per access, 1 single access).)
  [1:0] TXRDYM — Transmitter Ready Mode
    0=ONE_DATA (TXRDY will be at level '1' when at least one data can be written in the transmit FIFO. When DMA is enabled to transfer data, the chunk of 1 byte must be configured in the DMA. If the transfer is performed by software, the access type must be defined as byte.); 1=TWO_DATA (TXRDY will be at level '1' when at least two data can be written in the transmit FIFO. To minimize system bus load, when DMA is enabled to transfer data, the chunk of 1 halfword (1 halfword carries 2 bytes) must be configured in the DMA. If the transfer is performed by software, the access type can be defined as byte (1 byte per access, 2 accesses) or halfword (2 bytes per access, 1 single access).); 2=FOUR_DATA (TXRDY will be at level '1' when at least four data can be written in the transmit FIFO. To minimize system bus load, when DMA is enabled to transfer data, the chunk of 1 word (1 word carries 4 bytes) must be configured in the DMA. If the transfer is performed by software, the access type can be defined as byte (1 byte per access, 4 accesses), halfword (2 bytes per access, 2 accesses) or word (4 bytes per access, 1 single access).)
0x654 FLEX_TWI_FLR ro — TWI FIFO Level Register
  fields as FLEX_SPI_FLR
0x660 FLEX_TWI_FSR ro — TWI FIFO Status Register
  [7] RXFPTEF — Receive FIFO Pointer Error Flag
    values as FLEX_SPI_SR.RXFPTEF
  [6] TXFPTEF — Transmit FIFO Pointer Error Flag
    values as FLEX_SPI_SR.TXFPTEF
  [5] RXFTHF — Receive FIFO Threshold Flag
    0=Number of unread data in Receive FIFO is below RXFTHRES threshold; 1=Number of unread data in Receive FIFO has reached RXFTHRES threshold since the last read of FLEX_TWI_FSR
  [4] RXFFF — Receive FIFO Full Flag
    0=Receive FIFO is not empty; 1=Receive FIFO has been filled since the last read of FLEX_TWI_FSR
  [3] RXFEF — Receive FIFO Empty Flag
    0=Receive FIFO is not empty; 1=Receive FIFO has been emptied since the last read of FLEX_TWI_FSR
  [2] TXFTHF — Transmit FIFO Threshold Flag (cleared on read)
    0=Number of data in Transmit FIFO is above TXFTHRES threshold; 1=Number of data in Transmit FIFO has reached TXFTHRES threshold since the last read of FLEX_TWI_FSR
  [1] TXFFF — Transmit FIFO Full Flag (cleared on read)
    0=Transmit FIFO is not full; 1=Transmit FIFO has been filled since the last read of FLEX_TWI_FSR
  [0] TXFEF — Transmit FIFO Empty Flag (cleared on read)
    0=Transmit FIFO is not empty; 1=Transmit FIFO has been emptied since the last read of FLEX_TWI_FSR
0x664 FLEX_TWI_FIER wo — TWI FIFO Interrupt Enable Register
  [7] RXFPTEF — RXFPTEF Interrupt Enable
  [6] TXFPTEF — TXFPTEF Interrupt Enable
  [5] RXFTHF — RXFTHF Interrupt Enable
  [4] RXFFF — RXFFF Interrupt Enable
  [3] RXFEF — RXFEF Interrupt Enable
  [2] TXFTHF — TXFTHF Interrupt Enable
  [1] TXFFF — TXFFF Interrupt Enable
  [0] TXFEF — TXFEF Interrupt Enable
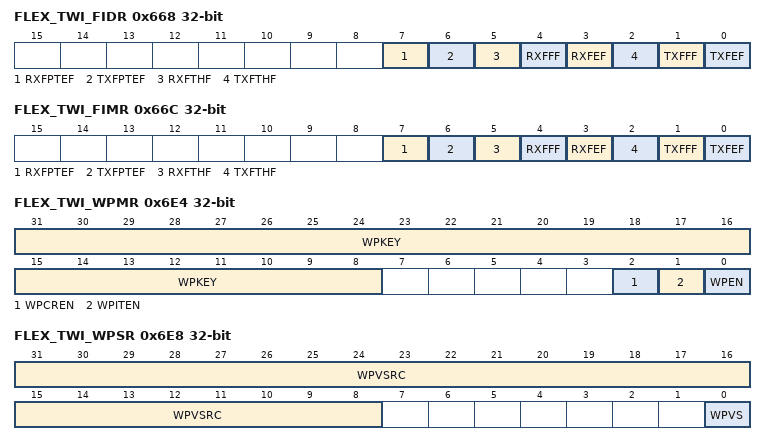
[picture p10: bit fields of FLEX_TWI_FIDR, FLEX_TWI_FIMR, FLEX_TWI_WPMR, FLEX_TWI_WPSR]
0x668 FLEX_TWI_FIDR wo — TWI FIFO Interrupt Disable Register
  [7] RXFPTEF — RXFPTEF Interrupt Disable
  [6] TXFPTEF — TXFPTEF Interrupt Disable
  [5] RXFTHF — RXFTHF Interrupt Disable
  [4] RXFFF — RXFFF Interrupt Disable
  [3] RXFEF — RXFEF Interrupt Disable
  [2] TXFTHF — TXFTHF Interrupt Disable
  [1] TXFFF — TXFFF Interrupt Disable
  [0] TXFEF — TXFEF Interrupt Disable
0x66C FLEX_TWI_FIMR ro — TWI FIFO Interrupt Mask Register
  [7] RXFPTEF — RXFPTEF Interrupt Mask
  [6] TXFPTEF — TXFPTEF Interrupt Mask
  [5] RXFTHF — RXFTHF Interrupt Mask
  [4] RXFFF — RXFFF Interrupt Mask
  [3] RXFEF — RXFEF Interrupt Mask
  [2] TXFTHF — TXFTHF Interrupt Mask
  [1] TXFFF — TXFFF Interrupt Mask
  [0] TXFEF — TXFEF Interrupt Mask
0x6E4 FLEX_TWI_WPMR — TWI Write Protection Mode Register
  [31:8] WPKEY — Write Protection Key
    0x545749=PASSWD (Writing any other value in this field aborts the write operation of bits WPEN, WPITEN and WPCREN. Always reads as 0)
  [2] WPCREN — Write Protection Control Enable
    0=Disables the write protection on control register if WPKEY corresponds to 0x545749 ('TWI' in ASCII); 1=Enables the write protection on control register if WPKEY corresponds to 0x545749 ('TWI' in ASCII)
  [1] WPITEN — Write Protection Interrupt Enable
    0=Disables the write protection on interrupt registers if WPKEY corresponds to 0x545749 ('TWI' in ASCII); 1=Enables the write protection on interrupt registers if WPKEY corresponds to 0x545749 ('TWI' in ASCII)
  [0] WPEN — Write Protection Enable
    0=Disables the write protection if WPKEY corresponds to 0x545749 ('TWI' in ASCII); 1=Enables the write protection if WPKEY corresponds to 0x545749 ('TWI' in ASCII)
0x6E8 FLEX_TWI_WPSR ro — TWI Write Protection Status Register
  [31:8] WPVSRC — Write Protection Violation Source
  [0] WPVS — Write Protect Violation Status (cleared on read)
    0=No Write Protection Violation has occurred since the last read of FLEX_TWI_WPSR; 1=A Write Protection Violation has occurred since the last read of FLEX_TWI_WPSR. If this violation is an unauthorized attempt to write a protected register, the associated violation is reported into field WPVSRC.
